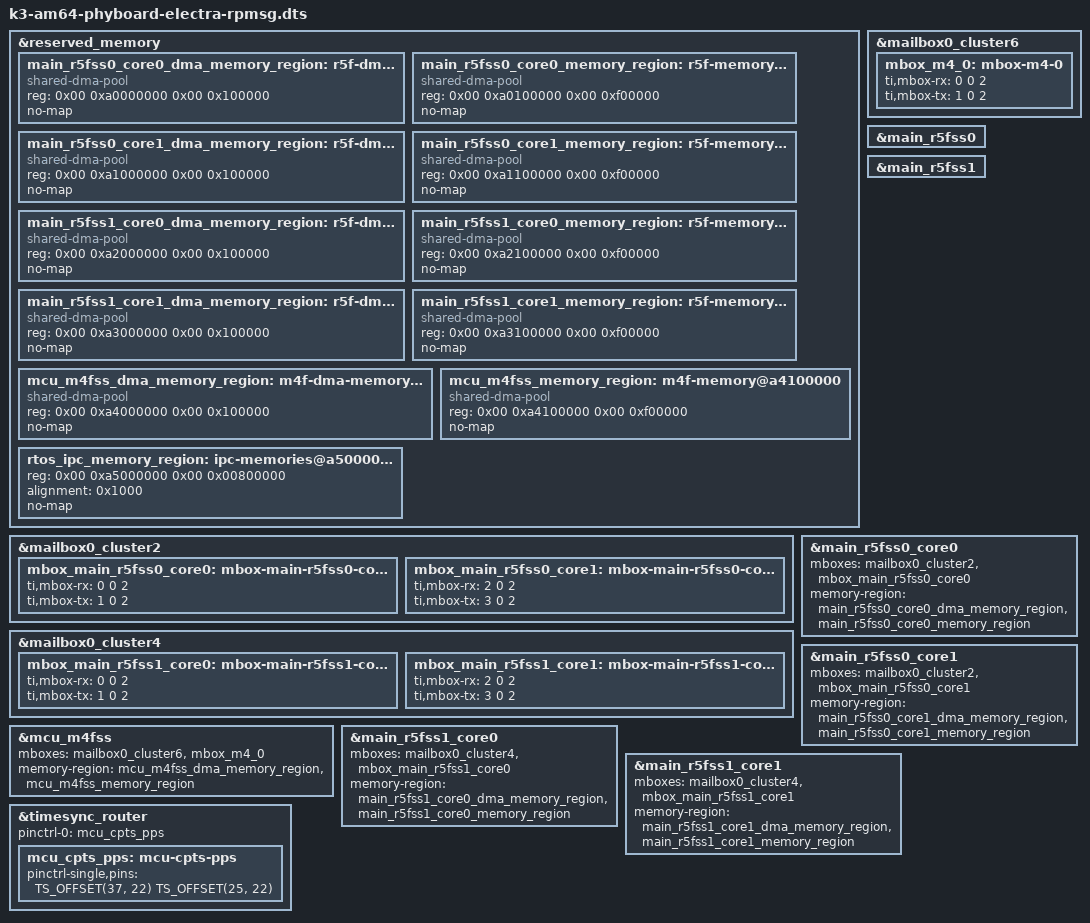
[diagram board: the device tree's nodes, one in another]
// SPDX-License-Identifier: GPL-2.0
/*
 * Copyright (C) 2022 PHYTEC Messtechnik GmbH
 * Author: Wadim Egorov <w.egorov@phytec.de>
 */

/dts-v1/;
/plugin/;

&reserved_memory {
	#address-cells = <2>;
	#size-cells = <2>;

	main_r5fss0_core0_dma_memory_region: r5f-dma-memory@a0000000 {
		compatible = "shared-dma-pool";
		reg = <0x00 0xa0000000 0x00 0x100000>;
		no-map;
	};

	main_r5fss0_core0_memory_region: r5f-memory@a0100000 {
		compatible = "shared-dma-pool";
		reg = <0x00 0xa0100000 0x00 0xf00000>;
		no-map;
	};

	main_r5fss0_core1_dma_memory_region: r5f-dma-memory@a1000000 {
		compatible = "shared-dma-pool";
		reg = <0x00 0xa1000000 0x00 0x100000>;
		no-map;
	};

	main_r5fss0_core1_memory_region: r5f-memory@a1100000 {
		compatible = "shared-dma-pool";
		reg = <0x00 0xa1100000 0x00 0xf00000>;
		no-map;
	};

	main_r5fss1_core0_dma_memory_region: r5f-dma-memory@a2000000 {
		compatible = "shared-dma-pool";
		reg = <0x00 0xa2000000 0x00 0x100000>;
		no-map;
	};

	main_r5fss1_core0_memory_region: r5f-memory@a2100000 {
		compatible = "shared-dma-pool";
		reg = <0x00 0xa2100000 0x00 0xf00000>;
		no-map;
	};

	main_r5fss1_core1_dma_memory_region: r5f-dma-memory@a3000000 {
		compatible = "shared-dma-pool";
		reg = <0x00 0xa3000000 0x00 0x100000>;
		no-map;
	};

	main_r5fss1_core1_memory_region: r5f-memory@a3100000 {
		compatible = "shared-dma-pool";
		reg = <0x00 0xa3100000 0x00 0xf00000>;
		no-map;
	};

	mcu_m4fss_dma_memory_region: m4f-dma-memory@a4000000 {
		compatible = "shared-dma-pool";
		reg = <0x00 0xa4000000 0x00 0x100000>;
		no-map;
	};

	mcu_m4fss_memory_region: m4f-memory@a4100000 {
		compatible = "shared-dma-pool";
		reg = <0x00 0xa4100000 0x00 0xf00000>;
		no-map;
	};

	rtos_ipc_memory_region: ipc-memories@a5000000 {
		reg = <0x00 0xa5000000 0x00 0x00800000>;
		alignment = <0x1000>;
		no-map;
	};
};

&mailbox0_cluster2 {
	status = "okay";

	mbox_main_r5fss0_core0: mbox-main-r5fss0-core0 {
		ti,mbox-rx = <0 0 2>;
		ti,mbox-tx = <1 0 2>;
	};

	mbox_main_r5fss0_core1: mbox-main-r5fss0-core1 {
		ti,mbox-rx = <2 0 2>;
		ti,mbox-tx = <3 0 2>;
	};
};

&mailbox0_cluster4 {
	status = "okay";

	mbox_main_r5fss1_core0: mbox-main-r5fss1-core0 {
		ti,mbox-rx = <0 0 2>;
		ti,mbox-tx = <1 0 2>;
	};

	mbox_main_r5fss1_core1: mbox-main-r5fss1-core1 {
		ti,mbox-rx = <2 0 2>;
		ti,mbox-tx = <3 0 2>;
	};
};

&mailbox0_cluster6 {
	status = "okay";

	mbox_m4_0: mbox-m4-0 {
		ti,mbox-rx = <0 0 2>;
		ti,mbox-tx = <1 0 2>;
	};
};

&main_r5fss0 {
	status = "okay";
};

&main_r5fss1 {
	status = "okay";
};

&mcu_m4fss {
	status = "okay";
};

&main_r5fss0_core0 {
	status = "okay";
	mboxes = <&mailbox0_cluster2 &mbox_main_r5fss0_core0>;
	memory-region = <&main_r5fss0_core0_dma_memory_region>,
			<&main_r5fss0_core0_memory_region>;
};

&main_r5fss0_core1 {
	status = "okay";
	mboxes = <&mailbox0_cluster2 &mbox_main_r5fss0_core1>;
	memory-region = <&main_r5fss0_core1_dma_memory_region>,
			<&main_r5fss0_core1_memory_region>;
};

&main_r5fss1_core0 {
	status = "okay";
	mboxes = <&mailbox0_cluster4 &mbox_main_r5fss1_core0>;
	memory-region = <&main_r5fss1_core0_dma_memory_region>,
			<&main_r5fss1_core0_memory_region>;
};

&main_r5fss1_core1 {
	status = "okay";
	mboxes = <&mailbox0_cluster4 &mbox_main_r5fss1_core1>;
	memory-region = <&main_r5fss1_core1_dma_memory_region>,
			<&main_r5fss1_core1_memory_region>;
};

&mcu_m4fss {
	status = "okay";
	mboxes = <&mailbox0_cluster6 &mbox_m4_0>;
	memory-region = <&mcu_m4fss_dma_memory_region>,
			<&mcu_m4fss_memory_region>;
};

#define TS_OFFSET(pa, val)     (0x4+(pa)*4) (0x10000 | val)

&timesync_router {
	status = "okay";
	pinctrl-names = "default";
	pinctrl-0 = <&mcu_cpts_pps>;

	/* Example of the timesync routing */
	mcu_cpts_pps: mcu-cpts-pps {
		pinctrl-single,pins = <
			/* pps [cpts genf1] in22 -> out37 [cpts hw8_push] */
			TS_OFFSET(37, 22)
			/* pps [cpts genf1] in22 -> out25 [SYNC1_OUT pin] */
			TS_OFFSET(25, 22)
		>;
	};
};
